# STM32H745_CM7 register map
File version: 2.5
CPU: CM7 r0p1, little endian, MPU, FPU, 4 interrupt priority bits
Registers are 32-bit, read-write, reset 0x0 unless marked. A register's access mark holds for its fields unless they carry their own. Offsets are from the block's base; [hi:lo] are bit positions; {n}, {i} and the like mark numbered series; 'fields as' and 'values as' point back to an identical list.

## EXTI — External interrupt/event controller
Base 0x58000000
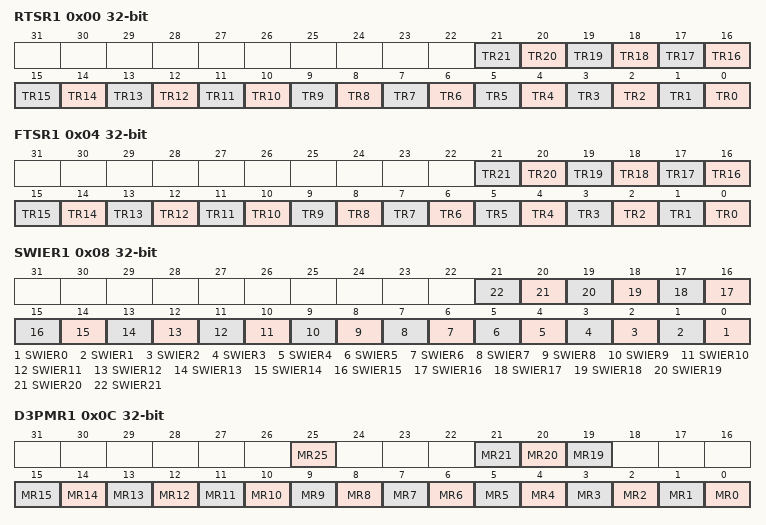
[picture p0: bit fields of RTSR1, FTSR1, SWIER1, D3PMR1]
0x00 RTSR1 — EXTI rising trigger selection register
  [all] fields
    0=Disabled (Rising edge trigger is disabled); 1=Enabled (Rising edge trigger is enabled)
  [n] TR{n} (n=0..21) — Rising trigger event configuration bit of Configurable Event input
0x04 FTSR1 — EXTI falling trigger selection register
  [all] fields
    0=Disabled (Falling edge trigger is disabled); 1=Enabled (Falling edge trigger is enabled)
  [n] TR{n} (n=0..21) — Rising trigger event configuration bit of Configurable Event input
0x08 SWIER1 — EXTI software interrupt event register
  [all] fields
    on write: 1=Pend (Generates an interrupt request)
  [n] SWIER{n} (n=0..21) — Rising trigger event configuration bit of Configurable Event input
0x0C D3PMR1 — EXTI D3 pending mask register
  [all] fields
    0=Masked (Interrupt request line is masked); 1=Unmasked (Interrupt request line is unmasked)
  [25] MR25 — Rising trigger event configuration bit of Configurable Event input
  [21] MR21 — Rising trigger event configuration bit of Configurable Event input
  [20] MR20 — Rising trigger event configuration bit of Configurable Event input
  [19] MR19 — Rising trigger event configuration bit of Configurable Event input
  [n] MR{n} (n=0..15) — Rising trigger event configuration bit of Configurable Event input
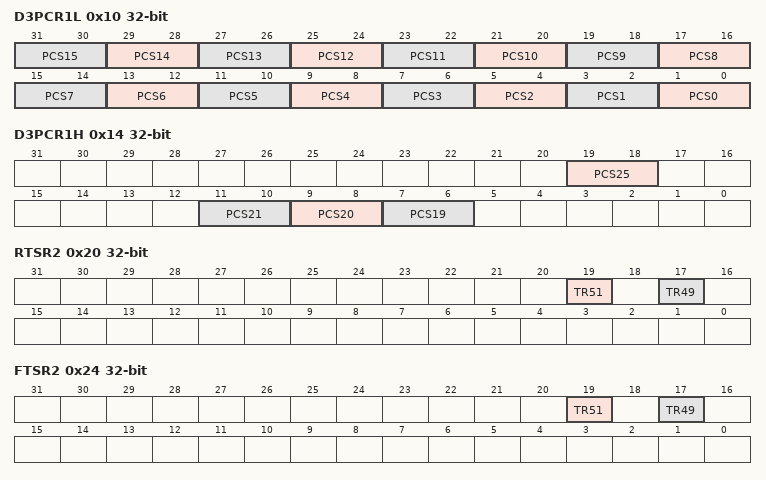
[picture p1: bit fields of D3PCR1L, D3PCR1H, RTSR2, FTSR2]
0x10 D3PCR1L — EXTI D3 pending clear selection register low
  [all] fields
    0=DMA_CH6 (DMA ch6 event selected as D3 domain pendclear source); 1=DMA_CH7 (DMA ch7 event selected as D3 domain pendclear source); 2=LPTIM4 (LPTIM4 out selected as D3 domain pendclear source); 3=LPTIM5 (LPTIM5 out selected as D3 domain pendclear source)
  [2n+1:2n] PCS{n} (n=0..15) — D3 Pending request clear input signal selection on Event input x = truncate (n/2)
0x14 D3PCR1H — EXTI D3 pending clear selection register high
  [all] fields
    values as the fields of D3PCR1L
  [19:18] PCS25 — D3 Pending request clear input signal selection on Event input x = truncate ((n+32)/2)
  [11:10] PCS21 — D3 Pending request clear input signal selection on Event input x = truncate ((n+32)/2)
  [9:8] PCS20 — D3 Pending request clear input signal selection on Event input x = truncate ((n+32)/2)
  [7:6] PCS19 — D3 Pending request clear input signal selection on Event input x = truncate ((n+32)/2)
0x20 RTSR2 — EXTI rising trigger selection register
  [19] TR51 — Rising trigger event configuration bit of Configurable Event input x+32
    values as the fields of RTSR1
  [17] TR49 — Rising trigger event configuration bit of Configurable Event input x+32
    values as the fields of RTSR1
0x24 FTSR2 — EXTI falling trigger selection register
  [19] TR51 — Falling trigger event configuration bit of Configurable Event input x+32
    values as the fields of FTSR1
  [17] TR49 — Falling trigger event configuration bit of Configurable Event input x+32
    values as the fields of FTSR1
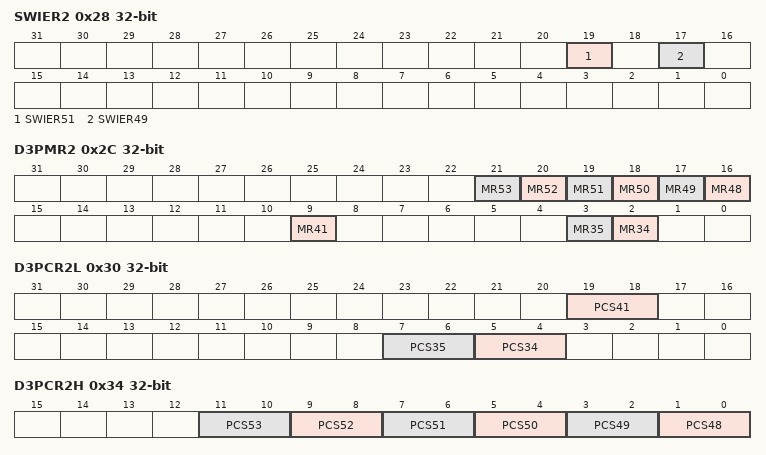
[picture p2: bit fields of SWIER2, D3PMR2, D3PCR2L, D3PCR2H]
0x28 SWIER2 — EXTI software interrupt event register
  [19] SWIER51 — Software interrupt on line x+32
    on write: 1=Pend (Generates an interrupt request)
  [17] SWIER49 — Software interrupt on line x+32
    on write: 1=Pend (Generates an interrupt request)
0x2C D3PMR2 — EXTI D3 pending mask register
  [all] fields
    values as the fields of D3PMR1
  [n-32] MR{n} (n=48..53) — D3 Pending Mask on Event input x+32
  [9] MR41 — D3 Pending Mask on Event input x+32
  [3] MR35 — D3 Pending Mask on Event input x+32
  [2] MR34 — D3 Pending Mask on Event input x+32
0x30 D3PCR2L — EXTI D3 pending clear selection register low
  [all] fields
    values as the fields of D3PCR1L
  [19:18] PCS41 — D3 Pending request clear input signal selection on Event input x = truncate ((n+64)/2)
  [7:6] PCS35 — D3 Pending request clear input signal selection on Event input x = truncate ((n+64)/2)
  [5:4] PCS34 — D3 Pending request clear input signal selection on Event input x = truncate ((n+64)/2)
0x34 D3PCR2H — EXTI D3 pending clear selection register high
  [all] fields
    values as the fields of D3PCR1L
  [2n-95:2n-96] PCS{n} (n=48..53) — Pending request clear input signal selection on Event input x= truncate ((n+96)/2)
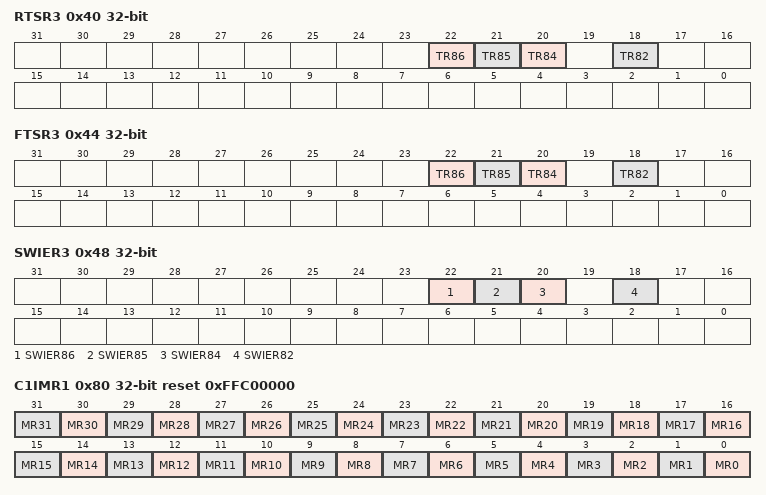
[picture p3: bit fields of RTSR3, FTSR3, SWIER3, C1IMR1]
0x40 RTSR3 — EXTI rising trigger selection register
  [all] fields
    values as the fields of RTSR1
  [22] TR86 — Rising trigger event configuration bit of Configurable Event input x+64
  [21] TR85 — Rising trigger event configuration bit of Configurable Event input x+64
  [20] TR84 — Rising trigger event configuration bit of Configurable Event input x+64
  [18] TR82 — Rising trigger event configuration bit of Configurable Event input x+64
0x44 FTSR3 — EXTI falling trigger selection register
  [all] fields
    values as the fields of FTSR1
  [22] TR86 — Falling trigger event configuration bit of Configurable Event input x+64
  [21] TR85 — Falling trigger event configuration bit of Configurable Event input x+64
  [20] TR84 — Falling trigger event configuration bit of Configurable Event input x+64
  [18] TR82 — Falling trigger event configuration bit of Configurable Event input x+64
0x48 SWIER3 — EXTI software interrupt event register
  [all] fields
    on write: 1=Pend (Generates an interrupt request)
  [22] SWIER86 — Software interrupt on line x+64
  [21] SWIER85 — Software interrupt on line x+64
  [20] SWIER84 — Software interrupt on line x+64
  [18] SWIER82 — Software interrupt on line x+64
0x4C D3PMR3 — EXTI D3 pending mask register
  [24] MR88 — D3 Pending Mask on Event input x+64
    values as the fields of D3PMR1
0x54 D3PCR3H — EXTI D3 pending clear selection register high
  [19:18] PCS88 — D3 Pending request clear input signal selection on Event input x= truncate N+160/2
    values as the fields of D3PCR1L
0x80 C1IMR1 reset 0xFFC00000 — EXTI interrupt mask register
  [all] fields
    values as the fields of D3PMR1
  [n] MR{n} (n=0..31) — Rising trigger event configuration bit of Configurable Event input
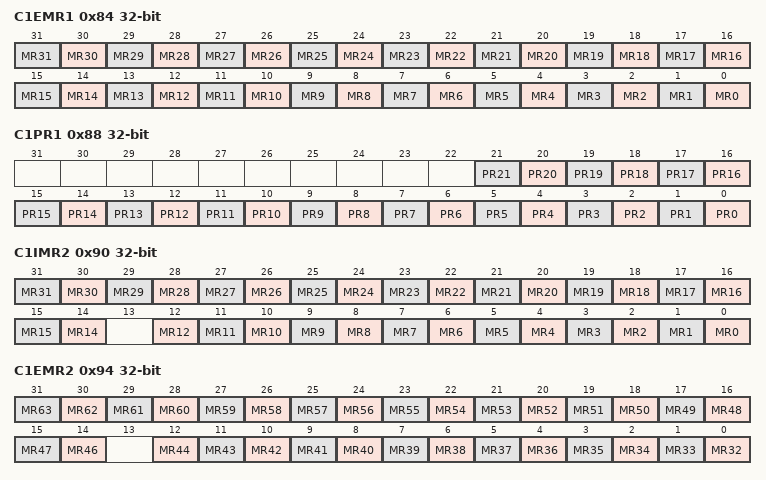
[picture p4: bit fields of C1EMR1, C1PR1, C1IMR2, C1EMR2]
0x84 C1EMR1 — EXTI event mask register
  [all] fields
    0=Masked (Event request line is masked); 1=Unmasked (Event request line is unmasked)
  [n] MR{n} (n=0..31) — CPU Event mask on Event input x
0x88 C1PR1 — EXTI pending register
  [all] fields
    on read: 0=NotPending (No trigger request occurred); 1=Pending (Selected trigger request occurred) | on write: 1=Clears pending bit
  [n] PR{n} write-1-clears (n=0..21) — CPU Event mask on Event input x
0x90 C1IMR2 — EXTI interrupt mask register
  [all] fields
    values as the fields of D3PMR1
  [n] MR{n} (n=14..31) — CPU Interrupt Mask on Direct Event input x+32
  [n] MR{n} (n=0..12) — CPU Interrupt Mask on Direct Event input x+32
0x94 C1EMR2 — EXTI event mask register
  [all] fields
    values as the fields of C1EMR1
  [n-32] MR{n} (n=46..63) — CPU Interrupt Mask on Direct Event input x+32
  [n-32] MR{n} (n=32..44) — CPU Interrupt Mask on Direct Event input x+32
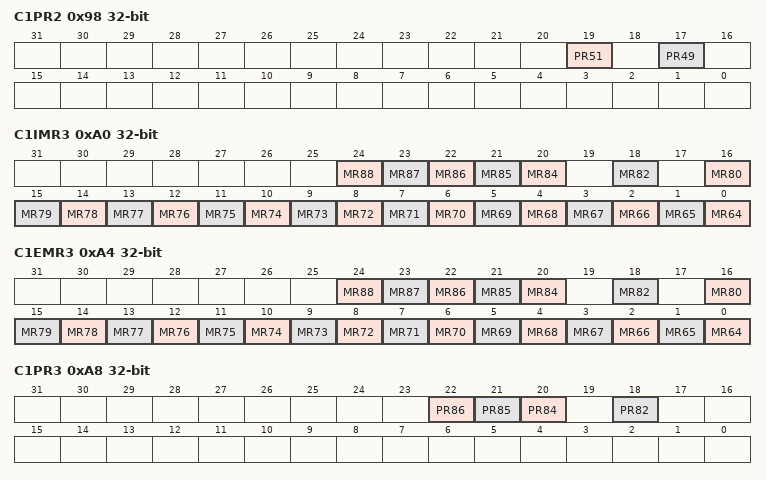
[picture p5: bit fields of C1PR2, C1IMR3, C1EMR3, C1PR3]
0x98 C1PR2 — EXTI pending register
  [19] PR51 write-1-clears — Configurable event inputs x+32 Pending bit
    values as the fields of C1PR1
  [17] PR49 write-1-clears — Configurable event inputs x+32 Pending bit
    values as the fields of C1PR1
0xA0 C1IMR3 — EXTI interrupt mask register
  [all] fields
    values as the fields of D3PMR1
  [n-64] MR{n} (n=84..88) — CPU Interrupt Mask on Direct Event input x+64
  [18] MR82 — CPU Interrupt Mask on Direct Event input x+64
  [n-64] MR{n} (n=64..80) — CPU Interrupt Mask on Direct Event input x+64
0xA4 C1EMR3 — EXTI event mask register
  [all] fields
    values as the fields of C1EMR1
  [n-64] MR{n} (n=84..88) — CPU Event mask on Event input x+64
  [18] MR82 — CPU Event mask on Event input x+64
  [n-64] MR{n} (n=64..80) — CPU Event mask on Event input x+64
0xA8 C1PR3 — EXTI pending register
  [all] fields
    values as the fields of C1PR1
  [22] PR86 write-1-clears — Configurable event inputs x+64 Pending bit
  [21] PR85 write-1-clears — Configurable event inputs x+64 Pending bit
  [20] PR84 write-1-clears — Configurable event inputs x+64 Pending bit
  [18] PR82 write-1-clears — Configurable event inputs x+64 Pending bit
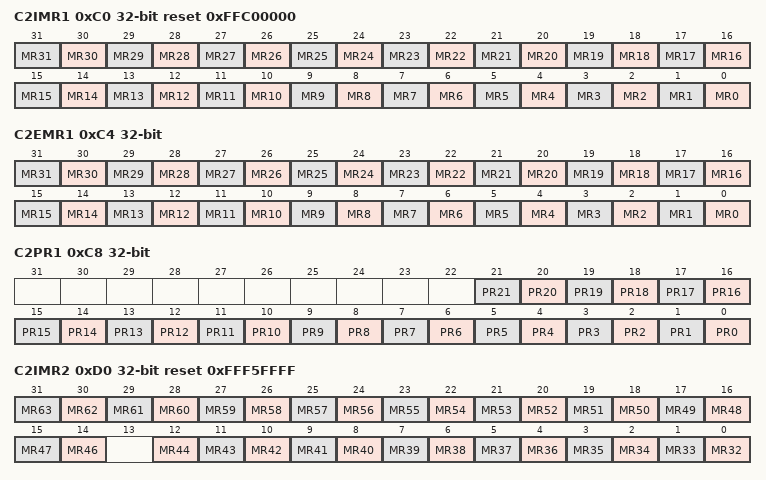
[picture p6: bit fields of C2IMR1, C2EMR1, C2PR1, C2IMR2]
0xC0 C2IMR1 access not given reset 0xFFC00000 — CPU2 EXTI interrupt mask register
  [all] fields
    values as the fields of D3PMR1
  [n] MR{n} (n=22..31) — CPU2 interrupt mask on Direct Event input
  [n] MR{n} (n=0..21) — CPU2 interrupt mask on Configurable Event input
0xC4 C2EMR1 access not given — CPU2 EXTI event mask register
  [all] fields
    values as the fields of C1EMR1
  [n] MR{n} (n=0..31) — CPU2 event mask on Event input x
0xC8 C2PR1 access not given — CPU2 EXTI pending register
  [all] fields
    values as the fields of C1PR1
  [n] PR{n} write-1-clears (n=0..21) — Configurable event input pending
0xD0 C2IMR2 access not given reset 0xFFF5FFFF — CPU2 EXTI interrupt mask register
  [all] fields
    values as the fields of D3PMR1
  [n-32] MR{n} (n=46..63) — CPU2 interrupt Mask on Direct Event input x+32
  [n-32] MR{n} (n=32..44) — CPU2 interrupt Mask on Direct Event input x+32
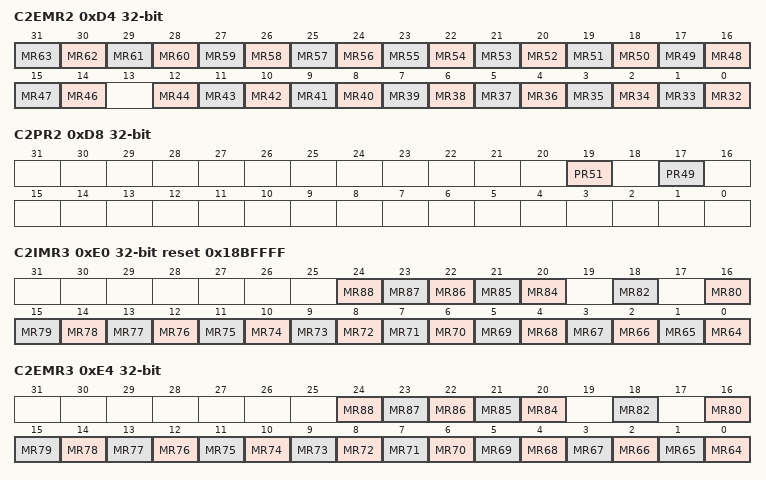
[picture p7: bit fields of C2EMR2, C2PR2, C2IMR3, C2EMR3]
0xD4 C2EMR2 access not given — CPU2 EXTI event mask register
  [all] fields
    values as the fields of C1EMR1
  [n-32] MR{n} (n=46..63) — CPU2 interrupt Mask on Direct Event input x+32
  [n-32] MR{n} (n=32..44) — CPU2 interrupt Mask on Direct Event input x+32
0xD8 C2PR2 access not given — CPU2 EXTI pending register
  [19] PR51 write-1-clears — CPU2 configurable event inputs x+32 Pending bit
    values as the fields of C1PR1
  [17] PR49 write-1-clears — CPU2 configurable event inputs x+32 Pending bit
    values as the fields of C1PR1
0xE0 C2IMR3 access not given reset 0x18BFFFF — CPU2 EXTI interrupt mask register
  [all] fields
    values as the fields of D3PMR1
  [n-64] MR{n} (n=84..88) — CPU2 interrupt Mask on Direct Event input x+64
  [18] MR82 — CPU2 interrupt Mask on Direct Event input x+64
  [n-64] MR{n} (n=64..80) — CPU2 interrupt Mask on Direct Event input x+64
0xE4 C2EMR3 access not given — CPU2 EXTI event mask register
  [all] fields
    values as the fields of C1EMR1
  [n-64] MR{n} (n=84..88) — CPU2 event mask on Event input x+64
  [18] MR82 — CPU2 event mask on Event input x+64
  [n-64] MR{n} (n=64..80) — CPU2 event mask on Event input x+64
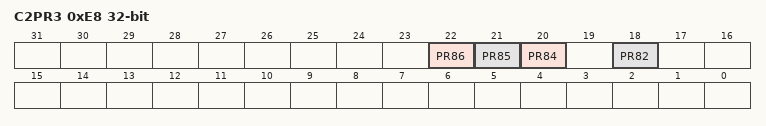
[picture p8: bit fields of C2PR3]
0xE8 C2PR3 access not given — CPU2 EXTI pending register
  [all] fields
    values as the fields of C1PR1
  [22] PR86 write-1-clears — CPU2 configurable event inputs x+64 Pending bit
  [21] PR85 write-1-clears — CPU2 configurable event inputs x+64 Pending bit
  [20] PR84 write-1-clears — CPU2 configurable event inputs x+64 Pending bit
  [18] PR82 write-1-clears — CPU2 configurable event inputs x+64 Pending bit
